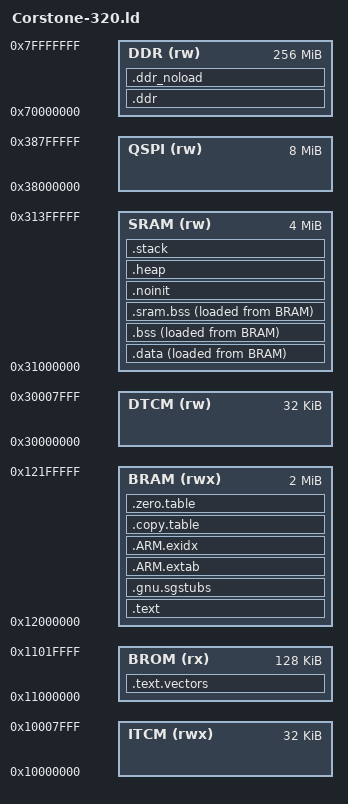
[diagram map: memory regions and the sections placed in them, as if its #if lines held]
/*
 * Copyright (c) 2025 Arm Limited. All rights reserved.
 *
 * SPDX-License-Identifier: Apache-2.0
 *
 * Licensed under the Apache License, Version 2.0 (the License); you may
 * not use this file except in compliance with the License.
 * You may obtain a copy of the License at
 *
 * www.apache.org/licenses/LICENSE-2.0
 *
 * Unless required by applicable law or agreed to in writing, software
 * distributed under the License is distributed on an AS IS BASIS, WITHOUT
 * WARRANTIES OR CONDITIONS OF ANY KIND, either express or implied.
 * See the License for the specific language governing permissions and
 * limitations under the License.
 */

__STACK_SIZE = 0x8000;
__HEAP_SIZE  = 0x10000;

/* ----------------------------------------------------------------------------
  Memory definition
 *----------------------------------------------------------------------------*/
MEMORY
{
  ITCM  (rwx) : ORIGIN = 0x10000000, LENGTH = 0x00008000
  BROM  (rx)  : ORIGIN = 0x11000000, LENGTH = 0x00020000
  BRAM  (rwx) : ORIGIN = 0x12000000, LENGTH = 0x00200000
  DTCM  (rw)  : ORIGIN = 0x30000000, LENGTH = 0x00008000
  SRAM  (rw)  : ORIGIN = 0x31000000, LENGTH = 0x00400000
  QSPI  (rw)  : ORIGIN = 0x38000000, LENGTH = 0x00800000
  DDR   (rw)  : ORIGIN = 0x70000000, LENGTH = 0x10000000
}

/* Linker script to place sections and symbol values. Should be used together
 * with other linker script that defines memory regions ROM and RAM.
 * It references following symbols, which must be defined in code:
 *   Reset_Handler : Entry of reset handler
 *
 * It defines following symbols, which code can use without definition:
 *   __exidx_start
 *   __exidx_end
 *   __copy_table_start__
 *   __copy_table_end__
 *   __zero_table_start__
 *   __zero_table_end__
 *   __etext          (deprecated)
 *   __data_start__
 *   __preinit_array_start
 *   __preinit_array_end
 *   __init_array_start
 *   __init_array_end
 *   __fini_array_start
 *   __fini_array_end
 *   __data_end__
 *   __bss_start__
 *   __bss_end__
 *   __noinit_start
 *   __noinit_end
 *   __end__
 *   end
 *   __HeapLimit
 *   __StackLimit
 *   __StackTop
 *   __stack
 */
ENTRY(Reset_Handler)

SECTIONS
{
  .text.vectors :
  {
    KEEP(*(.vectors))
  } > BROM

  .text :
  {
    *(.text*)

    KEEP(*(.init))
    KEEP(*(.fini))

    /* .ctors */
    *crtbegin.o(.ctors)
    *crtbegin?.o(.ctors)
    *(EXCLUDE_FILE(*crtend?.o *crtend.o) .ctors)
    *(SORT(.ctors.*))
    *(.ctors)

    /* .dtors */
    *crtbegin.o(.dtors)
    *crtbegin?.o(.dtors)
    *(EXCLUDE_FILE(*crtend?.o *crtend.o) .dtors)
    *(SORT(.dtors.*))
    *(.dtors)

    *(.rodata*)

    KEEP(*(.eh_frame*))
  } > BRAM

#if defined (__ARM_FEATURE_CMSE) && (__ARM_FEATURE_CMSE == 3U)
  .gnu.sgstubs :
  {
    . = ALIGN(32);
  } > BRAM
#endif

  .ARM.extab :
  {
    *(.ARM.extab* .gnu.linkonce.armextab.*)
  } > BRAM

  __exidx_start = .;
  .ARM.exidx :
  {
    *(.ARM.exidx* .gnu.linkonce.armexidx.*)

  } > BRAM
  __exidx_end = .;

  .copy.table :
  {
    . = ALIGN(4);
    __copy_table_start__ = .;

    LONG (LOADADDR(.data))
    LONG (ADDR(.data))
    LONG (SIZEOF(.data) / 4)

    __copy_table_end__ = .;
  } > BRAM

  .zero.table :
  {
    . = ALIGN(4);
    __zero_table_start__ = .;

    LONG (ADDR(.bss))
    LONG (SIZEOF(.bss) / 4)

    __zero_table_end__ = .;

  } > BRAM

  /*
   * This __etext variable is kept for backward compatibility with older,
   * ASM based startup files.
   */
  PROVIDE(__etext = LOADADDR(.data));

  .data : ALIGN(4)
  {
    __data_start__ = .;
    *(vtable)
    *(.data)
    *(.data.*)

    . = ALIGN(4);
    /* preinit data */
    PROVIDE_HIDDEN (__preinit_array_start = .);
    KEEP(*(.preinit_array))
    PROVIDE_HIDDEN (__preinit_array_end = .);

    . = ALIGN(4);
    /* init data */
    PROVIDE_HIDDEN (__init_array_start = .);
    KEEP(*(SORT(.init_array.*)))
    KEEP(*(.init_array))
    PROVIDE_HIDDEN (__init_array_end = .);

    . = ALIGN(4);
    /* finit data */
    PROVIDE_HIDDEN (__fini_array_start = .);
    KEEP(*(SORT(.fini_array.*)))
    KEEP(*(.fini_array))
    PROVIDE_HIDDEN (__fini_array_end = .);

    KEEP(*(.jcr*))
    . = ALIGN(4);
    /* All data end */
    __data_end__ = .;
  } > SRAM AT > BRAM

  .bss :
  {
    . = ALIGN(4);
    __bss_start__ = .;
    *(.bss)
    *(.bss.*)
    *(COMMON)
    . = ALIGN(4);
    __bss_end__ = .;
  } > SRAM AT > BRAM

  .sram.bss (NOLOAD) :
  {
    . = ALIGN(32);
    *(.bss.tensor_arena)
  } > SRAM AT > BRAM

  /* This section contains data that is not initialized during load,
     or during the application's initialization sequence. */
  .noinit (NOLOAD) :
  {
    . = ALIGN(4);
    __noinit_start = .;
    *(.noinit)
    *(.noinit.*)
    . = ALIGN(4);
    __noinit_end = .;
  } > SRAM

  .ddr :
  {
    . = ALIGN(16);
    *(network_model_sec)
    * (.got*)

  } > DDR

  .ddr_noload (NOLOAD) :
  {
    . = ALIGN(16);
    *(input_data_sec)
  } > DDR

  .heap (NOLOAD) :
  {
    . = ALIGN(8);
    __end__ = .;
    PROVIDE(end = .);
    . = . + __HEAP_SIZE;
    . = ALIGN(8);
    __HeapLimit = .;
  } > SRAM

  .stack (ORIGIN(SRAM) + LENGTH(SRAM) - __STACK_SIZE) (NOLOAD) :
  {
    . = ALIGN(8);
    __StackLimit = .;
    . = . + __STACK_SIZE;
    . = ALIGN(8);
    __StackTop = .;
  } > SRAM

  PROVIDE(__stack = __StackTop);

  /* Check if data + heap + stack exceeds RAM limit */
  ASSERT(__StackLimit >= __HeapLimit, "region RAM overflowed with stack")
}
